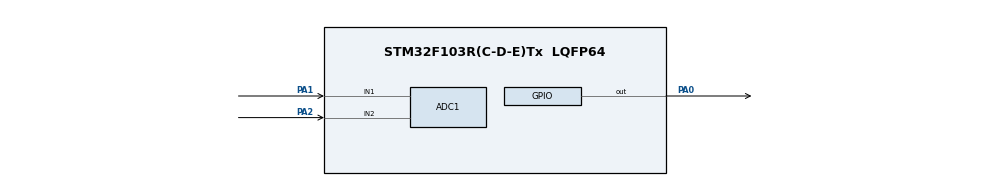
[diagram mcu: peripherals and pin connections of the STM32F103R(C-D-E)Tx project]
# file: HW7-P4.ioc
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ADC1.Channel-0\#ChannelRegularConversion=ADC_CHANNEL_1
ADC1.NbrOfConversionFlag=1
ADC1.Rank-0\#ChannelRegularConversion=1
ADC1.SamplingTime-0\#ChannelRegularConversion=ADC_SAMPLETIME_1CYCLE_5
ADC1.master=1
Mcu.Family=STM32F1
Mcu.Name=STM32F103R(C-D-E)Tx
Mcu.Package=LQFP64
NVIC.PriorityGroup=NVIC_PRIORITYGROUP_4
NVIC.TIM1_CC_IRQn=true\:0\:0\:false\:false\:true\:true\:true\:true
NVIC.TIM1_UP_IRQn=true\:0\:0\:false\:false\:true\:true\:true\:true
PA0-WKUP.Signal=GPIO_Output
PA1.Signal=ADCx_IN1
PA13.Mode=Serial_Wire
PA13.Signal=SYS_JTMS-SWDIO
PA14.Mode=Serial_Wire
PA14.Signal=SYS_JTCK-SWCLK
PA2.Signal=ADCx_IN2
ProjectManager.HeapSize=0x200
ProjectManager.StackSize=0x400
ProjectManager.TargetToolchain=MDK-ARM V5.32
RCC.APB1Freq_Value=8000000
RCC.APB2Freq_Value=8000000
SH.ADCx_IN1.0=ADC1_IN1,IN1
SH.ADCx_IN2.0=ADC1_IN2,IN2
TIM1.AutoReloadPreload=TIM_AUTORELOAD_PRELOAD_ENABLE
TIM1.Channel-Output\ Compare1\ No\ Output=TIM_CHANNEL_1
TIM1.OCMode_1=TIM_OCMODE_TOGGLE
TIM1.Period=new_arr
TIM1.Prescaler=PonePRE
TIM1.Pulse-Output\ Compare1\ No\ Output=0
TIM1.TIM_MasterOutputTrigger=TIM_TRGO_UPDATE
VP_TIM1_VS_ClockSourceINT.Mode=Internal
VP_TIM1_VS_no_output1.Mode=Output Compare1 No Output
board=custom

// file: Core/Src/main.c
/* USER CODE BEGIN Header */
/**
  ******************************************************************************
  * @file           : main.c
  * @brief          : Main program body
  ******************************************************************************
  * @attention
  *
  * Copyright (c) 2026 STMicroelectronics.
  * All rights reserved.
  *
  * This software is licensed under terms that can be found in the LICENSE file
  * in the root directory of this software component.
  * If no LICENSE file comes with this software, it is provided AS-IS.
  *
  ******************************************************************************
  */
/* USER CODE END Header */
#include "main.h"

ADC_HandleTypeDef hadc1;

TIM_HandleTypeDef htim1;

/* USER CODE BEGIN PV */
uint16_t PonePRE = 79;
uint32_t adc_freq = 0;
uint32_t adc_duty = 0;
uint32_t new_arr = 0;
uint32_t new_ccr = 0;
/* USER CODE END PV */

void SystemClock_Config(void);
static void MX_GPIO_Init(void);
static void MX_TIM1_Init(void);
static void MX_ADC1_Init(void);

/* USER CODE BEGIN 0 */
// Helper function to read a specific ADC channel
uint32_t Read_ADC_Channel(uint32_t channel)
{
    ADC_ChannelConfTypeDef sConfig = {0};
    sConfig.Channel = channel;
    sConfig.Rank = ADC_REGULAR_RANK_1;
    sConfig.SamplingTime = ADC_SAMPLETIME_1CYCLE_5;

    HAL_ADC_ConfigChannel(&hadc1, &sConfig);

    HAL_ADC_Start(&hadc1);
    HAL_ADC_PollForConversion(&hadc1, 10);
    return HAL_ADC_GetValue(&hadc1);
}

void HAL_TIM_PeriodElapsedCallback(TIM_HandleTypeDef *htim){
    if(TIM1->CCR1 > 0){
        HAL_GPIO_WritePin(GPIOA, GPIO_PIN_0, GPIO_PIN_SET);
    }
}

void HAL_TIM_OC_DelayElapsedCallback(TIM_HandleTypeDef *htim){
    if(htim->Channel == HAL_TIM_ACTIVE_CHANNEL_1){
        HAL_GPIO_WritePin(GPIOA, GPIO_PIN_0, GPIO_PIN_RESET);
    }
}
/* USER CODE END 0 */

int main(void)
{

  /* MCU Configuration--------------------------------------------------------*/

  /* Reset of all peripherals, Initializes the Flash interface and the Systick. */
  HAL_Init();

  /* Configure the system clock */
  SystemClock_Config();

  /* Initialize all configured peripherals */
  MX_GPIO_Init();
  MX_TIM1_Init();
  MX_ADC1_Init();

  /* Infinite loop */
  /* USER CODE BEGIN WHILE */
  while (1)
  {
		// Read both potentiometers
      adc_freq = Read_ADC_Channel(ADC_CHANNEL_1); // PA1
      adc_duty = Read_ADC_Channel(ADC_CHANNEL_2); // PA2

      if (adc_freq < 5)
      {
          HAL_TIM_Base_Stop_IT(&htim1);
          HAL_TIM_OC_Stop_IT(&htim1, TIM_CHANNEL_1);
          HAL_GPIO_WritePin(GPIOA, GPIO_PIN_0, GPIO_PIN_RESET);
      }
      else
      {
          HAL_TIM_Base_Start_IT(&htim1);
          HAL_TIM_OC_Start_IT(&htim1, TIM_CHANNEL_1);

          // 1. Calculate and set new ARR (Frequency)
          new_arr = (409500 / adc_freq) - 1;
          if (new_arr > 65535) new_arr = 65535;

          // 2. Calculate and set new CCR1 (Duty Cycle) relative to the new ARR
          new_ccr = (adc_duty * (new_arr + 1)) / 4095;

          TIM1->ARR = new_arr;
          TIM1->CCR1 = new_ccr;
      }

      HAL_Delay(10);
    /* USER CODE END WHILE */

  }
}

void SystemClock_Config(void)
{
  RCC_OscInitTypeDef RCC_OscInitStruct = {0};
  RCC_ClkInitTypeDef RCC_ClkInitStruct = {0};
  RCC_PeriphCLKInitTypeDef PeriphClkInit = {0};

  /** Initializes the RCC Oscillators according to the specified parameters
  * in the RCC_OscInitTypeDef structure.
  */
  RCC_OscInitStruct.OscillatorType = RCC_OSCILLATORTYPE_HSI;
  RCC_OscInitStruct.HSIState = RCC_HSI_ON;
  RCC_OscInitStruct.HSICalibrationValue = RCC_HSICALIBRATION_DEFAULT;
  RCC_OscInitStruct.PLL.PLLState = RCC_PLL_NONE;
  if (HAL_RCC_OscConfig(&RCC_OscInitStruct) != HAL_OK)
  {
    Error_Handler();
  }

  /** Initializes the CPU, AHB and APB buses clocks
  */
  RCC_ClkInitStruct.ClockType = RCC_CLOCKTYPE_HCLK|RCC_CLOCKTYPE_SYSCLK
                              |RCC_CLOCKTYPE_PCLK1|RCC_CLOCKTYPE_PCLK2;
  RCC_ClkInitStruct.SYSCLKSource = RCC_SYSCLKSOURCE_HSI;
  RCC_ClkInitStruct.AHBCLKDivider = RCC_SYSCLK_DIV1;
  RCC_ClkInitStruct.APB1CLKDivider = RCC_HCLK_DIV1;
  RCC_ClkInitStruct.APB2CLKDivider = RCC_HCLK_DIV1;

  if (HAL_RCC_ClockConfig(&RCC_ClkInitStruct, FLASH_LATENCY_0) != HAL_OK)
  {
    Error_Handler();
  }
  PeriphClkInit.PeriphClockSelection = RCC_PERIPHCLK_ADC;
  PeriphClkInit.AdcClockSelection = RCC_ADCPCLK2_DIV2;
  if (HAL_RCCEx_PeriphCLKConfig(&PeriphClkInit) != HAL_OK)
  {
    Error_Handler();
  }
}

static void MX_ADC1_Init(void)
{

  ADC_ChannelConfTypeDef sConfig = {0};

  /** Common config
  */
  hadc1.Instance = ADC1;
  hadc1.Init.ScanConvMode = ADC_SCAN_DISABLE;
  hadc1.Init.ContinuousConvMode = DISABLE;
  hadc1.Init.DiscontinuousConvMode = DISABLE;
  hadc1.Init.ExternalTrigConv = ADC_SOFTWARE_START;
  hadc1.Init.DataAlign = ADC_DATAALIGN_RIGHT;
  hadc1.Init.NbrOfConversion = 1;
  if (HAL_ADC_Init(&hadc1) != HAL_OK)
  {
    Error_Handler();
  }

  /** Configure Regular Channel
  */
  sConfig.Channel = ADC_CHANNEL_1;
  sConfig.Rank = ADC_REGULAR_RANK_1;
  sConfig.SamplingTime = ADC_SAMPLETIME_1CYCLE_5;
  if (HAL_ADC_ConfigChannel(&hadc1, &sConfig) != HAL_OK)
  {
    Error_Handler();
  }

}

static void MX_TIM1_Init(void)
{

  TIM_ClockConfigTypeDef sClockSourceConfig = {0};
  TIM_MasterConfigTypeDef sMasterConfig = {0};
  TIM_OC_InitTypeDef sConfigOC = {0};
  TIM_BreakDeadTimeConfigTypeDef sBreakDeadTimeConfig = {0};

  htim1.Instance = TIM1;
  htim1.Init.Prescaler = PonePRE;
  htim1.Init.CounterMode = TIM_COUNTERMODE_UP;
  htim1.Init.Period = new_arr;
  htim1.Init.ClockDivision = TIM_CLOCKDIVISION_DIV1;
  htim1.Init.RepetitionCounter = 0;
  htim1.Init.AutoReloadPreload = TIM_AUTORELOAD_PRELOAD_ENABLE;
  if (HAL_TIM_Base_Init(&htim1) != HAL_OK)
  {
    Error_Handler();
  }
  sClockSourceConfig.ClockSource = TIM_CLOCKSOURCE_INTERNAL;
  if (HAL_TIM_ConfigClockSource(&htim1, &sClockSourceConfig) != HAL_OK)
  {
    Error_Handler();
  }
  if (HAL_TIM_OC_Init(&htim1) != HAL_OK)
  {
    Error_Handler();
  }
  sMasterConfig.MasterOutputTrigger = TIM_TRGO_UPDATE;
  sMasterConfig.MasterSlaveMode = TIM_MASTERSLAVEMODE_DISABLE;
  if (HAL_TIMEx_MasterConfigSynchronization(&htim1, &sMasterConfig) != HAL_OK)
  {
    Error_Handler();
  }
  sConfigOC.OCMode = TIM_OCMODE_TOGGLE;
  sConfigOC.Pulse = 0;
  sConfigOC.OCPolarity = TIM_OCPOLARITY_HIGH;
  sConfigOC.OCNPolarity = TIM_OCNPOLARITY_HIGH;
  sConfigOC.OCFastMode = TIM_OCFAST_DISABLE;
  sConfigOC.OCIdleState = TIM_OCIDLESTATE_RESET;
  sConfigOC.OCNIdleState = TIM_OCNIDLESTATE_RESET;
  if (HAL_TIM_OC_ConfigChannel(&htim1, &sConfigOC, TIM_CHANNEL_1) != HAL_OK)
  {
    Error_Handler();
  }
  sBreakDeadTimeConfig.OffStateRunMode = TIM_OSSR_DISABLE;
  sBreakDeadTimeConfig.OffStateIDLEMode = TIM_OSSI_DISABLE;
  sBreakDeadTimeConfig.LockLevel = TIM_LOCKLEVEL_OFF;
  sBreakDeadTimeConfig.DeadTime = 0;
  sBreakDeadTimeConfig.BreakState = TIM_BREAK_DISABLE;
  sBreakDeadTimeConfig.BreakPolarity = TIM_BREAKPOLARITY_HIGH;
  sBreakDeadTimeConfig.AutomaticOutput = TIM_AUTOMATICOUTPUT_DISABLE;
  if (HAL_TIMEx_ConfigBreakDeadTime(&htim1, &sBreakDeadTimeConfig) != HAL_OK)
  {
    Error_Handler();
  }

}

static void MX_GPIO_Init(void)
{
  GPIO_InitTypeDef GPIO_InitStruct = {0};

  /* GPIO Ports Clock Enable */
  __HAL_RCC_GPIOA_CLK_ENABLE();

  /*Configure GPIO pin Output Level */
  HAL_GPIO_WritePin(GPIOA, GPIO_PIN_0, GPIO_PIN_RESET);

  /*Configure GPIO pin : PA0 */
  GPIO_InitStruct.Pin = GPIO_PIN_0;
  GPIO_InitStruct.Mode = GPIO_MODE_OUTPUT_PP;
  GPIO_InitStruct.Pull = GPIO_NOPULL;
  GPIO_InitStruct.Speed = GPIO_SPEED_FREQ_LOW;
  HAL_GPIO_Init(GPIOA, &GPIO_InitStruct);

}

void Error_Handler(void)
{
  __disable_irq();
  while (1)
  {
  }
}
